# PIC32CZ4010CA90176S1 device description
Architecture: CORTEX-M0PLUS; Family: PIC32CZ; Series: PIC32CZCA90
Registers are 32-bit, read-write, reset 0x0 unless marked. A register's access mark holds for its fields unless they carry their own. Offsets are from the block's base; [hi:lo] are bit positions; {n}, {i} and the like mark numbered series; 'fields as' and 'values as' point back to an identical list.

## AUXINTF — Auxiliary Interface
Instances: AI 0x57000100
0x00 AIOFFSET (atomic set) — Auxiliary Interface Address Offset
  [31:0] OFFSET — Address Offset
0x04 AIATTR — Auxiliary Interface Attributes
  [0] NSM — Non Secure Master

## CSM — Control and Status Module
Instances: CSM 0x57000000
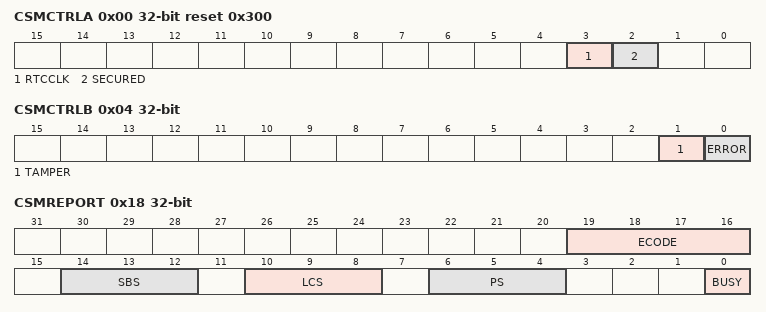
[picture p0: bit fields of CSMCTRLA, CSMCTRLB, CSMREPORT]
0x00 CSMCTRLA reset 0x300 — CSM Control register A
  [3] RTCCLK — RTC Clock Enable bit
  [2] SECURED — Secured bit
0x04 CSMCTRLB — CSM Control register B
  [1] TAMPER — Tamper Interrupt Request bit.
  [0] ERROR — Error Interrupt Request bit.
0x08 CSMINTENCLR ro (atomic clear) — CSM INTERRUPT ENABLE Clear register
  [0] CANCEL — Cancel Command Interrupt Enable bit
0x0C CSMINTENSET (atomic set) — CSM INTERRUPT ENABLE SET register
  [0] CANCEL — Cancel Command Interrupt Enable bit
0x10 CSMINTFLAG ro (atomic clear) — CSM INTERRUPT FLAG register
  [0] CANCEL — Cancel Command Interrupt Flag bit
0x14 CSMSTATUS ro
  [0] OTPLOCK — OTP Lock bit
0x18 CSMREPORT
  [19:16] ECODE — Error Code
  [14:12] SBS — Secure Boot State bits
  [10:8] LCS — Lifecycle State bits
  [6:4] PS — Processing State bits
  [0] BUSY — HSM CPU Busy

## EXTDMA — External DMA Module
Instances: EXTDMA 0x52000800
0x00 FETCH_ADDR_LSB — Lower Fetch Address
  [31:0] ADDR — Address
0x04 FETCH_ADDR_MSB — Upper Fetch Address
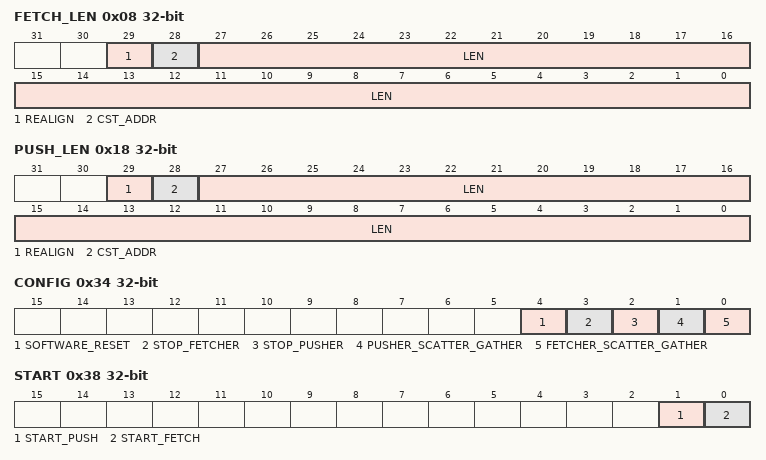
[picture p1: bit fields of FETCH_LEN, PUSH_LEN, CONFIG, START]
0x08 FETCH_LEN — Fetch Length
  [29] REALIGN
  [28] CST_ADDR — CST Address
  [27:0] LEN — Length of data block
0x0C FETCH_TAG
  [31:0] TAG — User TAG
0x10 PUSH_ADDR_LSB — Lower Push Address
  [31:0] ADDR — Address
0x14 PUSH_ADDR_MSB — Upper Fetch Address
0x18 PUSH_LEN — Push Length
  fields as FETCH_LEN
0x1C INT_EN reset not defined — Interrupt Enable
0x20 INT_ENSET reset not defined (atomic set of INT_EN) — Interrupt Enable Set
0x24 INT_ENCLR reset not defined (atomic clear of INT_EN) — Interrupt Enable Clear
0x28 INT_STATRAW reset not defined — Interrupt Raw Status
0x2C INT_STAT reset not defined — Interrupt Status
0x30 INT_STAT_CLR reset not defined (atomic clear) — Interrupt Status Clear
0x34 CONFIG reset not defined — Configuraiton
  [4] SOFTWARE_RESET, [3] STOP_FETCHER, [2] STOP_PUSHER, [1] PUSHER_SCATTER_GATHER, [0] FETCHER_SCATTER_GATHER
0x38 START reset not defined
  [1] START_PUSH, [0] START_FETCH
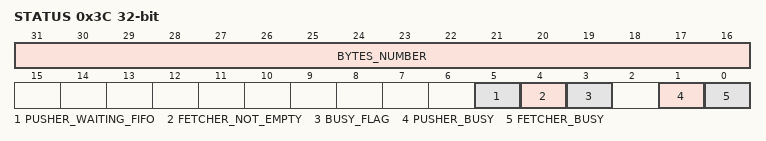
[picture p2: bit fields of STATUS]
0x3C STATUS reset not defined — Stop
  [31:16] BYTES_NUMBER, [5] PUSHER_WAITING_FIFO, [4] FETCHER_NOT_EMPTY, [3] BUSY_FLAG, [1] PUSHER_BUSY, [0] FETCHER_BUSY

## INTCTRL — eSecure Interrupt Controller Module
Instances: INTCTRL 0x52000400
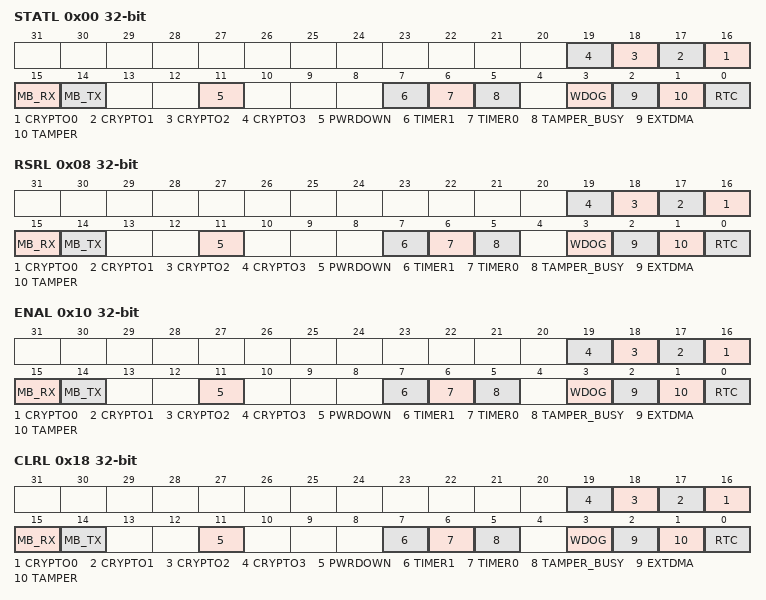
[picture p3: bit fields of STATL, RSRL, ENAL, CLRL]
0x00 STATL ro — Interrupt Status Register Low
  [n+16] CRYPTO{n} (n=0..3) — Crypto Interrupt {n}
  [15] MB_RX — Mailbox RX Interrupt
  [14] MB_TX — Mailbox TX Interrupt
  [11] PWRDOWN — Power Down Interrupt
  [7] TIMER1 — Timer 1 interrupt
  [6] TIMER0 — Timer 0 Interrupt
  [5] TAMPER_BUSY — Tamper Busy Interrupt
  [3] WDOG — Watch Dog Interrupt
  [2] EXTDMA — External DMA Interrupt
  [1] TAMPER — Tamper Interrupt
  [0] RTC — RTC Interrupt
0x08 RSRL (atomic clear) — Interrupt Raw Status Register Low
  fields as STATL
0x10 ENAL (atomic set) — Interrupt Enable Register Low
  fields as STATL
0x18 CLRL wo (atomic clear) — Interrupt Disable Register Low
  fields as STATL
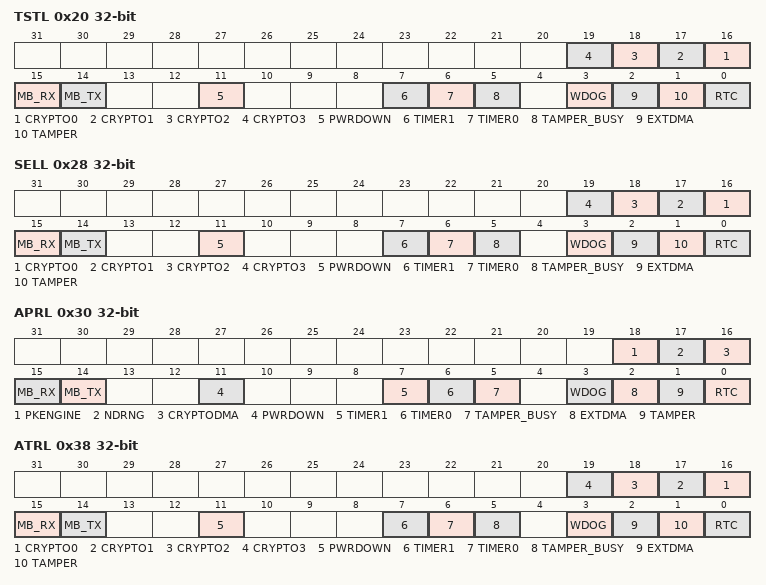
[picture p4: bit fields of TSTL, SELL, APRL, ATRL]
0x20 TSTL — Interrupt Test Source Register Low
  fields as STATL
0x28 SELL — Interrupt Source Selection Register Low
  fields as STATL
0x30 APRL — Interrupt Activation Polarity Register Low
  [18] PKENGINE — PK Engine Interrupt
  [17] NDRNG — RNG Interrupt
  [16] CRYPTODMA — Crypto DMA Interrupt
  [15] MB_RX — Mailbox RX Interrupt
  [14] MB_TX — Mailbox TX Interrupt
  [11] PWRDOWN — Power Down Interrupt
  [7] TIMER1 — Timer 1 interrupt
  [6] TIMER0 — Timer 0 Interrupt
  [5] TAMPER_BUSY — Tamper Busy Interrupt
  [3] WDOG — Watch Dog Interrupt
  [2] EXTDMA — External DMA Interrupt
  [1] TAMPER — Tamper Interrupt
  [0] RTC — RTC Interrupt
0x38 ATRL — Interrupt Activation Type Register Low
  fields as STATL
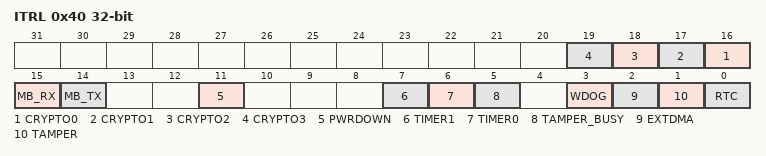
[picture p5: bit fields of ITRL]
0x40 ITRL — Interrupt Type register Low
  fields as STATL
0x48 PIN ro — Interrupt Pending IRQ Num
  [5:0] PIN — Pending IRQ Num

## Notices in the file
Copyright (c) 2021 Microchip Technology Inc.
SPDX-License-Identifier: Apache-2.0
Licensed under the Apache License, Version 2.0 (the "License");
you may not use this file except in compliance with the License.
You may obtain a copy of the License at
http://www.apache.org/licenses/LICENSE-2.0
Unless required by applicable law or agreed to in writing, software
distributed under the License is distributed on an "AS IS" BASIS,
WITHOUT WARRANTIES OR CONDITIONS OF ANY KIND, either express or implied.
See the License for the specific language governing permissions and
limitations under the License.
